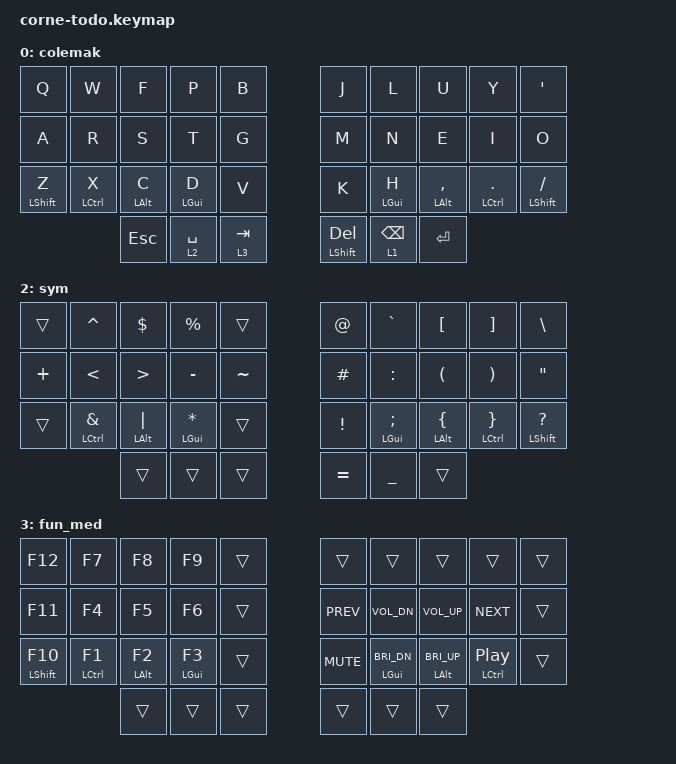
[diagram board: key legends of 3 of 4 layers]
#define ___ &trans

#include <behaviors.dtsi>
#include <dt-bindings/zmk/keys.h>
#include <dt-bindings/zmk/bt.h>


/ {
    chosen {
        zmk,physical-layout = &foostan_corne_5col_layout;
    };

    // NOTE: unfortunately hold-trigger-key-positions and
    // hold-trigger-on-release don't work if you quickly hit a key not in
    // hold-trigger-key-positions and then try and do a hold. With rpi it's
    // fine since the idle ms is long enough.
    behaviors {
        blt: balanced_layer_tap {
            compatible = "zmk,behavior-hold-tap";
            flavor = "balanced";
            bindings = <&mo>, <&kp>;
            #binding-cells = <2>;
            tapping-term-ms = <200>;
            quick-tap-ms = <200>;
        };
        bmt: balanced_mod_tap {
            compatible = "zmk,behavior-hold-tap";
            flavor = "balanced";
            bindings = <&kp>, <&kp>;
            #binding-cells = <2>;
            tapping-term-ms = <200>;
            quick-tap-ms = <200>;
        };
    };

    keymap {
        compatible = "zmk,keymap";

        colemak {
            bindings = <
&kp Q               &kp W               &kp F               &kp P               &kp B               &kp J               &kp L               &kp U               &kp Y               &kp SQT
&kp A               &kp R               &kp S               &kp T               &kp G               &kp M               &kp N               &kp E               &kp I               &kp O
&bmt LSHIFT Z       &bmt LCTRL X        &bmt LALT C         &bmt LGUI D         &kp V               &kp K               &bmt LGUI H         &bmt LALT COMMA     &bmt LCTRL DOT      &bmt LSHIFT FSLH
                                        &kp ESC             &blt 2 SPACE        &blt 3 TAB          &bmt LSHIFT DEL     &blt 1 BSPC         &kp RET
            >;
        };

        num_nav {
            bindings = <
___                 &kp N7              &kp N8              &kp N9              &kp LA(LC(F))       &kp CAPS            &kp LA(BSPC)        &caps_word          ___                 ___
&kp N0              &kp N4              &kp N5              &kp N6              &kp F13             &kp LEFT            &kp DOWN            &kp UP              &kp RIGHT           &bmt LSHIFT LS(RET)
___                 &bmt LCTRL N1       &bmt LALT N2        &bmt LGUI N3        ___                 &kp HOME            &bmt LGUI PG_DN     &bmt LALT PG_UP     &bmt LCTRL END      ___
                                        ___                 &kp PG_DN           &kp PG_UP           &kp HOME            &kp END             ___
                                        &kp ESC             &blt 2 SPACE        &blt 3 TAB          &bmt LSHIFT DEL     &blt 1 BSPC         &kp RET
            >;
        };

        sym {
            bindings = <
___                 &kp CARET           &kp DLLR            &kp PRCNT           ___                 &kp AT              &kp GRAVE           &kp LBKT            &kp RBKT            &kp BSLH
&kp PLUS            &kp LT              &kp GT              &kp MINUS           &kp TILDE           &kp HASH            &kp COLON           &kp LPAR            &kp RPAR            &kp DQT
___                 &bmt LCTRL AMPS     &bmt LALT PIPE      &bmt LGUI STAR      ___                 &kp EXCL            &bmt LGUI SEMI      &bmt LALT LBRC      &bmt LCTRL RBRC     &bmt LSHIFT QMARK
                                        ___                 ___                 ___                 &kp EQUAL           &kp UNDER           ___
            >;
        };

        fun_med {
            bindings = <
&kp F12             &kp F7              &kp F8              &kp F9              ___                 ___                 ___                 ___                 ___                 ___
&kp F11             &kp F4              &kp F5              &kp F6              ___                 &kp C_PREV          &kp C_VOL_DN        &kp C_VOL_UP        &kp C_NEXT          ___
&bmt LSHIFT F10     &bmt LCTRL F1       &bmt LALT F2        &bmt LGUI F3        ___                 &kp C_MUTE          &bmt LGUI C_BRI_DN  &bmt LALT C_BRI_UP  &bmt LCTRL C_PP     ___
                                        ___                 ___                 ___                 ___                 ___                 ___
            >;
        };
    };
};
